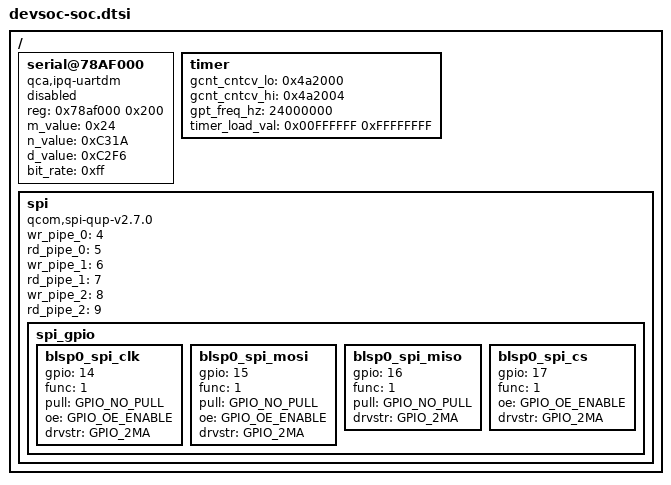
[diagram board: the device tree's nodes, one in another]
/*
 * Copyright (c) 2016-2019, The Linux Foundation. All rights reserved.
 *
 * Copyright (c) 2022 Qualcomm Innovation Center, Inc. All rights reserved.
 *
 * This program is free software; you can redistribute it and/or modify
 * it under the terms of the GNU General Public License version 2 and
 * only version 2 as published by the Free Software Foundation.
 *
 * This program is distributed in the hope that it will be useful,
 * but WITHOUT ANY WARRANTY; without even the implied warranty of
 * MERCHANTABILITY or FITNESS FOR A PARTICULAR PURPOSE.  See the
 * GNU General Public License for more details.
 */

#include "skeleton.dtsi"
#include <dt-bindings/qcom/gpio-devsoc.h>

/ {
	serial@78AF000 {
		compatible = "qca,ipq-uartdm";
		reg = <0x78af000 0x200>;
		m_value = <0x24>;
		n_value = <0xC31A>;
		d_value = <0xC2F6>;
		bit_rate = <0xff>;
		status = "disabled";
	};

	timer {
		gcnt_cntcv_lo = <0x4a2000>;
		gcnt_cntcv_hi = <0x4a2004>;
		gpt_freq_hz = <24000000>;
		timer_load_val = <0x00FFFFFF 0xFFFFFFFF>;
	};

	spi {
		compatible = "qcom,spi-qup-v2.7.0";
		wr_pipe_0 = <4>;
		rd_pipe_0 = <5>;
		wr_pipe_1 = <6>;
		rd_pipe_1 = <7>;
		wr_pipe_2 = <8>;
		rd_pipe_2 = <9>;
		status = "ok";
		spi_gpio {
			blsp0_spi_clk {
				gpio = <14>;
				func = <1>;
				pull = <GPIO_NO_PULL>;
				oe = <GPIO_OE_ENABLE>;
				drvstr = <GPIO_2MA>;
			};
			blsp0_spi_mosi {
				gpio = <15>;
				func = <1>;
				pull = <GPIO_NO_PULL>;
				oe = <GPIO_OE_ENABLE>;
				drvstr = <GPIO_2MA>;
			};
			blsp0_spi_miso {
				gpio = <16>;
				func = <1>;
				pull = <GPIO_NO_PULL>;
				drvstr = <GPIO_2MA>;
			};
			blsp0_spi_cs {
				gpio = <17>;
				func = <1>;
				oe = <GPIO_OE_ENABLE>;
				drvstr = <GPIO_2MA>;
			};
		};
	};
};
